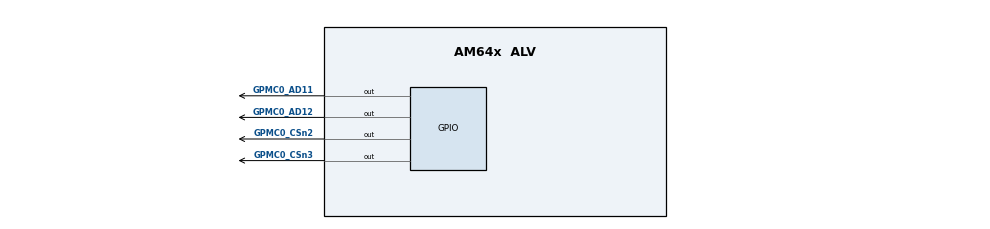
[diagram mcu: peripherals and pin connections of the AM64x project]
/**
 * @cliArgs --device "AM64x" --package "ALV" --part "Default" --context "a53ss0-0" --product "MCU_PLUS_SDK@07.03.01"
 * @versions {"tool":"1.20.0+3587"}
 */

/**
 * Import the modules used in this configuration.
 */
const eqep       = scripting.addModule("/drivers/eqep/eqep", {}, false);
const eqep1      = eqep.addInstance();
const gpio       = scripting.addModule("/drivers/gpio/gpio", {}, false);
const gpio1      = gpio.addInstance();
const gpio2      = gpio.addInstance();
const gpio3      = gpio.addInstance();
const gpio4      = gpio.addInstance();
const debug_log  = scripting.addModule("/kernel/dpl/debug_log");
const dpl_cfg = scripting.addModule("/kernel/dpl/dpl_cfg");
const mmu_armv8  = scripting.addModule("/kernel/dpl/mmu_armv8", {}, false);
const mmu_armv81 = mmu_armv8.addInstance();
const mmu_armv82 = mmu_armv8.addInstance();
const mmu_armv83 = mmu_armv8.addInstance();

/**
 * Write custom configuration values to the imported modules.
 */
eqep1.$name = "CONFIG_EQEP0";

gpio1.$name                = "CONFIG_GPIO0";
gpio1.pinDir               = "OUTPUT";
gpio1.GPIO.gpioPin.rx      = false;
gpio1.GPIO.gpioPin.$assign = "GPMC0_AD11";

gpio2.$name                = "CONFIG_GPIO1";
gpio2.pinDir               = "OUTPUT";
gpio2.GPIO.gpioPin.rx      = false;
gpio2.GPIO.gpioPin.$assign = "GPMC0_AD12";

gpio3.$name                = "CONFIG_GPIO2";
gpio3.pinDir               = "OUTPUT";
gpio3.GPIO.gpioPin.rx      = false;
gpio3.GPIO.gpioPin.$assign = "GPMC0_CSn2";

gpio4.$name                = "CONFIG_GPIO3";
gpio4.pinDir               = "OUTPUT";
gpio4.GPIO.gpioPin.$assign = "GPMC0_CSn3";

debug_log.enableCssLog         = false;
debug_log.enableUartLog        = true;
debug_log.uartLog.$name        = "CONFIG_UART_CONSOLE";
debug_log.uartLog.UART.$assign = "USART0";

const uart_v0_template  = scripting.addModule("/drivers/uart/v0/uart_v0_template", {}, false);
const uart_v0_template1 = uart_v0_template.addInstance({}, false);
uart_v0_template1.$name = "drivers_uart_v0_uart_v0_template0";
debug_log.uartLog.child = uart_v0_template1;

mmu_armv81.size  = 0x80000000;
mmu_armv81.$name = "SOC_MEM_REGION";

mmu_armv82.vAddr     = 0x70000000;
mmu_armv82.pAddr     = 0x70000000;
mmu_armv82.size      = 0x200000;
mmu_armv82.attribute = "MAIR7";
mmu_armv82.$name     = "MSRAM_REGION";

mmu_armv83.vAddr     = 0x80000000;
mmu_armv83.pAddr     = 0x80000000;
mmu_armv83.size      = 0x80000000;
mmu_armv83.attribute = "MAIR7";
mmu_armv83.$name     = "DDR_REGION";

/**
 * Pinmux solution for unlocked pins/peripherals. This ensures that minor changes to the automatic solver in a future
 * version of the tool will not impact the pinmux you originally saw.  These lines can be completely deleted in order to
 * re-solve from scratch.
 */
eqep1.EQEP.$suggestSolution                 = "EQEP0";
eqep1.EQEP.A.$suggestSolution               = "GPMC0_WPn";
eqep1.EQEP.B.$suggestSolution               = "GPMC0_DIR";
eqep1.EQEP.I.$suggestSolution               = "GPMC0_CSn1";
eqep1.EQEP.S.$suggestSolution               = "GPMC0_CSn0";
gpio1.GPIO.$suggestSolution                 = "GPIO0";
gpio2.GPIO.$suggestSolution                 = "GPIO0";
gpio3.GPIO.$suggestSolution                 = "GPIO0";
gpio4.GPIO.$suggestSolution                 = "GPIO0";
debug_log.uartLog.UART.RXD.$suggestSolution = "UART0_RXD";
debug_log.uartLog.UART.TXD.$suggestSolution = "UART0_TXD";
